AUTOSAR XML (schema 4-2-2)
package /Components
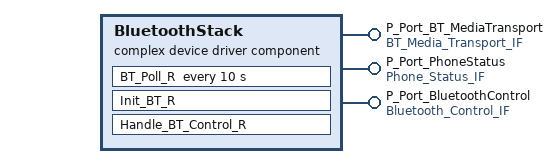
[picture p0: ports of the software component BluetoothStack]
  complex device driver sw component type BluetoothStack
    provide port P_Port_BT_MediaTransport: provided-interface=BT_Media_Transport_IF
    provide port P_Port_PhoneStatus: provided-interface=Phone_Status_IF
    provide port P_Port_BluetoothControl: provided-interface=Bluetooth_Control_IF
    behavior BluetoothStack_Internal
      init event BT_Init: start-on-event=Init_BT_R
      operation invoked event BT_Control_Called: start-on-event=Handle_BT_Control_R
      timing event BT_Poll: start-on-event=BT_Poll_R, period=10
      runnable Init_BT_R
        parameter access ParamInit_SampleRate: accessed-parameter=P_Port_BT_MediaTransport.sample_rate_hz
        parameter access ParamInit_Channels: accessed-parameter=P_Port_BT_MediaTransport.channels
      runnable BT_Poll_R: minimum-start-interval=10
        data-send-points:
          5 x access:
            Send_AudioFrame: accessed-variable=P_Port_BT_MediaTransport.audio_pcm_frame
            Send_SampleRate: accessed-variable=P_Port_BT_MediaTransport.sample_rate_hz
            Send_Channels: accessed-variable=P_Port_BT_MediaTransport.channels
            Send_CallState: accessed-variable=P_Port_PhoneStatus.call_state
            Send_CallerId: accessed-variable=P_Port_PhoneStatus.caller_id
      runnable Handle_BT_Control_R
        data-send-points:
          access Send_ImmediateCallState: accessed-variable=P_Port_PhoneStatus.call_state
          access Send_ImmediateCallerId: accessed-variable=P_Port_PhoneStatus.caller_id
        data-write-access:
          access Write_SampleRate: accessed-variable=P_Port_BT_MediaTransport.sample_rate_hz
          access Write_Channels: accessed-variable=P_Port_BT_MediaTransport.channels
          access Write_CallState: accessed-variable=P_Port_PhoneStatus.call_state
